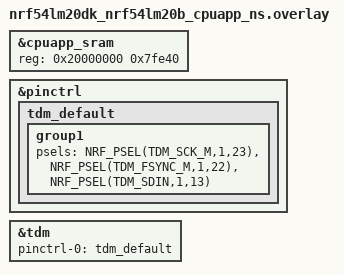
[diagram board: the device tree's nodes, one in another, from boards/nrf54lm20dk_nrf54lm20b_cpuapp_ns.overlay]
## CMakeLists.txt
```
#
# Copyright (c) 2018 Nordic Semiconductor
#
# SPDX-License-Identifier: LicenseRef-Nordic-5-Clause
#
cmake_minimum_required(VERSION 3.20.0)

find_package(Zephyr REQUIRED HINTS $ENV{ZEPHYR_BASE})
project(NONE)

# NORDIC SDK APP START
target_sources(app PRIVATE
  src/main.c
  src/beamform.c
  src/bluetooth.c
)

# NORDIC SDK APP END
```

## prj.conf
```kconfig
#
# Copyright (c) 2018 Nordic Semiconductor
#
# SPDX-License-Identifier: LicenseRef-Nordic-5-Clause
#

# Enable the UART driver
CONFIG_UART_ASYNC_API=y
CONFIG_NRFX_UARTE=y
CONFIG_SERIAL=y

CONFIG_GPIO=y

# Make sure printk is printing to the UART console
CONFIG_CONSOLE=y
CONFIG_UART_CONSOLE=y

CONFIG_HEAP_MEM_POOL_SIZE=300000
# sized for ~8 seconds of 16kHz mono audio

CONFIG_BT=y
CONFIG_BT_PERIPHERAL=y
CONFIG_BT_DEVICE_NAME="iLab-BeamformerProto"
CONFIG_BT_MAX_CONN=1
CONFIG_BT_MAX_PAIRED=1

# Enable the NUS service
CONFIG_BT_NUS=y

# Enable bonding
CONFIG_BT_SETTINGS=y
CONFIG_FLASH=y
CONFIG_FLASH_PAGE_LAYOUT=y
CONFIG_FLASH_MAP=y

# Enable DK LED and Buttons library
CONFIG_DK_LIBRARY=y

CONFIG_SYSTEM_WORKQUEUE_STACK_SIZE=2048
# Config logger
CONFIG_LOG=y
CONFIG_USE_SEGGER_RTT=y
CONFIG_LOG_BACKEND_RTT=y
CONFIG_LOG_BACKEND_UART=n
CONFIG_LOG_PRINTK=n

CONFIG_ASSERT=y

CONFIG_BT_L2CAP_TX_MTU=247
CONFIG_BT_BUF_ACL_TX_SIZE=251
CONFIG_BT_BUF_ACL_RX_SIZE=251
CONFIG_BT_CTLR_DATA_LENGTH_MAX=251

CONFIG_I2S=y
```

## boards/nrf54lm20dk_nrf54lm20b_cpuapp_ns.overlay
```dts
/*
 * Copyright (c) 2026 N›ordic Semiconductor ASA
 *
 * SPDX-License-Identifier: LicenseRef-Nordic-5-Clause
 */

 #include <dt-bindings/pinctrl/nrf-pinctrl.h>

&cpuapp_sram {
	reg = <0x20000000 0x7fe40>;
	ranges = <0x0 0x20000000 0x7fe40>;
};

&pinctrl {
	tdm_default: tdm_default {
		group1 {
			psels = <NRF_PSEL(TDM_SCK_M,1,23)>,
				<NRF_PSEL(TDM_FSYNC_M,1,22)>,
				<NRF_PSEL(TDM_SDIN,1,13)>;
		};
	};
};

&tdm {
	status = "okay";
	pinctrl-0 = <&tdm_default>;
	pinctrl-names = "default";
};
```

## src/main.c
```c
#include <zephyr/kernel.h>
#include <zephyr/logging/log.h>
#include <zephyr/sys/atomic.h>
#include <zephyr/sys/util.h>
#include <dk_buttons_and_leds.h>

#include "beamform.h"
#include "bluetooth.h"

LOG_MODULE_REGISTER(main, LOG_LEVEL_INF);

enum audio_state {
	STATE_IDLE = BIT(0),
	STATE_LISTENING = BIT(1),
	STATE_FINALIZE = BIT(2),
	STATE_PROCESSING = BIT(3),
	STATE_RESPONDING = BIT(4),
};

static atomic_t audio_state = ATOMIC_INIT(STATE_IDLE);
static atomic_t capture_enabled = ATOMIC_INIT(0);

static void enter_state(enum audio_state next_state) {
	atomic_set(&audio_state, next_state);

	switch(next_state) {
		case STATE_IDLE:
			atomic_clear(&capture_enabled);
			LOG_INF("STATE_IDLE");
			break;
		
		case STATE_LISTENING:
			atomic_set(&capture_enabled, 1);
			LOG_INF("STATE_LISTENING: capture_enabled=1");
			break;
		
		case STATE_FINALIZE:
			atomic_clear(&capture_enabled);
			LOG_INF("STATE_FINALIZE: capture_enabled=0, draining BLE TX queue");
			break;
		
		case STATE_PROCESSING:
			atomic_clear(&capture_enabled);
			LOG_INF("STATE_PROCESSING");
			break;
		
		case STATE_RESPONDING:
			atomic_clear(&capture_enabled);
			LOG_INF("STATE_RESPONDING");
			break;
		
		default:
			LOG_ERR("Invalid state: 0x%x", next_state);
			atomic_set(&audio_state, STATE_IDLE);
			atomic_clear(&capture_enabled);
			break;
	}
}

static void on_beamformed_chunk(const int16_t *samples, size_t count) {
	if (!atomic_get(&capture_enabled)) {
		return;
	}

	int err = bluetooth_enqueue_audio(samples, count);

	if(err) {
		LOG_WRN("BLE TX queue rejected audio chunk: %d", err);
	}
}

static void button_changed(uint32_t state, uint32_t changed) {
	uint32_t pressed = state & changed;
	enum audio_state current = atomic_get(&audio_state);

	// IDLE -> LISTENING
	if ((pressed & DK_BTN1_MSK) && current == STATE_IDLE) {
		enter_state(STATE_LISTENING);
	}
	
	// LISTENING -> FINALIZE
	if ((pressed & DK_BTN2_MSK) && current == STATE_LISTENING) {
		enter_state(STATE_FINALIZE);
	}
}

static void finalize_processing(void) {
	enum audio_state current = atomic_get(&audio_state);

	if(current == STATE_FINALIZE && bluetooth_tx_drained()) {
		enter_state(STATE_PROCESSING);

		// fill in other behavior for processing

		enter_state(STATE_IDLE);
	}
}

int main(void) {
	int err = dk_leds_init();
	if(err) return err;
	err = dk_buttons_init(button_changed);
	if(err) return err;
	err = bluetooth_init();
	if(err) return err;
	err = beamform_init(on_beamformed_chunk);
	if(err) return err;
	err = beamform_start();
	if(err) {
		LOG_ERR("Always-on beamforming failed to start: %d", err);
		return err;
	}

	enter_state(STATE_IDLE);
	LOG_INF("Always-on beamforming active\nBTN1: IDLE->LISTENING, BTN2: LISTENING->FINALIZE");

	for (;;) {
		finalize_processing();
		k_sleep(K_MSEC(10));
	}
}
```

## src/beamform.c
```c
#include <errno.h>
#include <zephyr/device.h>
#include <zephyr/devicetree.h>
#include <zephyr/drivers/i2s.h>
#include <zephyr/kernel.h>
#include <zephyr/logging/log.h>
#include <zephyr/sys/atomic.h>

LOG_MODULE_REGISTER(beamform);

#define SAMPLE_RATE 16000
#define CHANNELS    2
#define BLOCK_PAIRS 256
#define BLOCK_BYTES (BLOCK_PAIRS * CHANNELS * sizeof(int16_t))
#define MAX_SAMPLES (SAMPLE_RATE * 8) 

#define TDM_NODE DT_NODELABEL(tdm)

K_MEM_SLAB_DEFINE(rx_slab, BLOCK_BYTES, 4, 4);
K_THREAD_STACK_DEFINE(capture_stack, 2048);

static const struct device *const i2s = DEVICE_DT_GET(TDM_NODE);
static const struct i2s_config i2s_cfg = {
    .word_size = 16,
    .channels = CHANNELS,
    .format = I2S_FMT_DATA_FORMAT_I2S,
    .options = I2S_OPT_BIT_CLK_CONT | I2S_OPT_FRAME_CLK_MASTER,
    .frame_clk_freq = SAMPLE_RATE,
    .mem_slab = &rx_slab,
    .block_size = BLOCK_BYTES,
    .timeout = 2000,
};

static int16_t mono[MAX_SAMPLES];
static size_t mono_count;
static atomic_t recording = ATOMIC_INIT(0);
static atomic_t audio_ready = ATOMIC_INIT(0);
static struct k_thread capture_thread_data;
static void (*recording_done)(void);

static void capture(void *a, void *b, void *c) {
    ARG_UNUSED(a);
    ARG_UNUSED(b);
    ARG_UNUSED(c);

    if(i2s_trigger(i2s, I2S_DIR_RX, I2S_TRIGGER_START)) {
        atomic_clear(&recording);
        return;
    }

    while (atomic_get(&recording) && mono_count < MAX_SAMPLES) {
        void *block;
        size_t bytes;
        int err = i2s_read(i2s, &block, &bytes);

        if(err) {
            if (err == -EAGAIN) {
                continue;
            }
            break;
        }

        int16_t *stereo = block;
        size_t pairs = bytes/ (CHANNELS * sizeof(int16_t));
        for (size_t i =0; i < pairs && mono_count < MAX_SAMPLES; i++) {
            // beamforming algorithm:
            mono[mono_count++] = ((int32_t)stereo[2*i] + stereo[2*i+1])/2;
        }
        k_mem_slab_free(&rx_slab, block);
    }

    i2s_trigger(i2s, I2S_DIR_RX, I2S_TRIGGER_DROP);
    atomic_clear(&recording);
    atomic_set(&audio_ready, 1);
    if(recording_done) {
        recording_done();
    }
}

int beamform_init(void (*done_cb)(void)) {
    recording_done = done_cb;
    if(!device_is_ready(i2s)) {
        return -ENODEV;
    }
    return i2s_configure(i2s, I2S_DIR_RX, &i2s_cfg);
}

int beamform_start(void) {
    if(atomic_get(&recording) || atomic_get(&audio_ready)) {
        return -EBUSY;
    }

    mono_count = 0;
    atomic_set(&recording,1);
    k_thread_create(&capture_thread_data, capture_stack, 
        K_THREAD_STACK_SIZEOF(capture_stack), capture, NULL, NULL, NULL,
        6, 0, K_NO_WAIT);
    return 0;
}

void beamform_stop(void) {
    atomic_clear(&recording);
    i2s_trigger(i2s, I2S_DIR_RX, I2S_TRIGGER_DROP);
}

bool beamform_has_audio(void) {
    return atomic_get(&audio_ready);
}

const int16_t *beamform_audio(void) {
    return mono;
}

size_t beamform_audio_count(void) {
    return mono_count;
}

void beamform_clear(void) {
    mono_count = 0;
    atomic_clear(&audio_ready);
}
```

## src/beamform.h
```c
#ifndef BEAMFORM_H_
#define BEAMFORM_H_

#include <stddef.h>
#include <stdint.h>
#include <stdbool.h>

int beamform_init(void (*done_cb)(void));
int beamform_start(void);
void beamform_stop(void);

bool beamform_has_audio(void);
const int16_t *beamform_audio(void);
size_t beamform_audio_count(void);
void beamform_clear(void);

#endif
```

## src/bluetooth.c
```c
#include <errno.h>
#include <string.h>
#include <zephyr/bluetooth/bluetooth.h>
#include <zephyr/bluetooth/conn.h>
#include <zephyr/bluetooth/gatt.h>
#include <zephyr/kernel.h>
#include <zephyr/logging/log.h>
#include <zephyr/sys/atomic.h>
#include <bluetooth/services/nus.h>

#include "bluetooth.h"

LOG_MODULE_REGISTER(bluetooth, LOG_LEVEL_INF);

#define DEVICE_NAME CONFIG_BT_DEVICE_NAME
#define DEVICE_NAME_LEN (sizeof(DEVICE_NAME) - 1)

#define AUDIO_CHUNK_SAMPLES 256
#define AUDIO_QUEUE_DEPTH 8

struct audio_chunk {
    size_t samples;
    int16_t pcm[AUDIO_CHUNK_SAMPLES];
};

K_MSGQ_DEFINE(audio_tx_queue, sizeof(struct audio_chunk), AUDIO_QUEUE_DEPTH, 4);
K_THREAD_STACK_DEFINE(ble_tx_stack, 2048);

static struct bt_conn *connection;
static atomic_t subscribed = ATOMIC_INIT(0);
static atomic_t tx_busy = ATOMIC_INIT(0);
static struct k_thread ble_tx_thread_data;

static const struct bt_data ad[] = {
    BT_DATA_BYTES(BT_DATA_FLAGS, BT_LE_AD_GENERAL | BT_LE_AD_NO_BREDR),
    BT_DATA(BT_DATA_NAME_COMPLETE, DEVICE_NAME, DEVICE_NAME_LEN),
};
static const struct bt_data sd[] = {
    BT_DATA_BYTES(BT_DATA_UUID128_ALL, BT_UUID_NUS_VAL),
};

static bool bluetooth_ready(void) {
    return connection != NULL && atomic_get(&subscribed);
}

static void connected(struct bt_conn *conn, uint8_t err) {
    if(err) {
        LOG_WRN("BLE connection failed: %u", err);
        return;
    }

    connection = bt_conn_ref(conn);
    LOG_INF("BLE connected");
}

static void disconnected(struct bt_conn *conn, uint8_t reason) {
    ARG_UNUSED(conn);
    ARG_UNUSED(reason);

    atomic_clear(&subscribed);

    if(connection) {
        bt_conn_unref(connection);
        connection = NULL;
    }

    LOG_INF("BLE disconnected");
    bt_le_adv_start(BT_LE_ADV_CONN_FAST_2, ad, ARRAY_SIZE(ad), sd, 
        ARRAY_SIZE(sd));
}

BT_CONN_CB_DEFINE(conn_callbacks) = {
    .connected = connected,
    .disconnected = disconnected,
};

static void nus_send_enabled(enum bt_nus_send_status status) {
    atomic_set(&subscribed, status == BT_NUS_SEND_STATUS_ENABLED);
    LOG_INF("NUS notifications %s", atomic_get(&subscribed) ? "enabled" : "disabled");
}

static struct bt_nus_cb nus_cb = {
    .send_enabled = nus_send_enabled,
};

static int send_chunk(const struct audio_chunk *chunk) {
    if (!bluetooth_ready()) {
        return -ENOTCONN;
    }

    uint16_t mtu = bt_gatt_get_mtu(connection);
    size_t samples_per_packet = MAX((size_t)1, (mtu-3) / sizeof(int16_t));

    for(size_t offset = 0; offset < chunk->samples; offset += samples_per_packet) {
        size_t count = MIN(samples_per_packet, chunk->samples - offset);
        int err = bt_nus_send(NULL, (const uint8_t *)&chunk->pcm[offset], count*sizeof(int16_t));

        if(err) return err;

        k_sleep(K_MSEC(1));
    }

    return 0;
}


static void ble_tx_worker(void *a, void *b, void *c) {
    ARG_UNUSED(a);
    ARG_UNUSED(b);
    ARG_UNUSED(c);

    while(true) {
        struct audio_chunk chunk;
        int err = k_msgq_get(&audio_tx_queue, &chunk, K_FOREVER);
        if (err) continue;

        atomic_set(&tx_busy, 1);

        while(!bluetooth_ready()) {
            k_sleep(K_MSEC(20));
        }

        err = send_chunk(&chunk);
        if(err) {
            LOG_WRN("BLE send failed; dropped one chunk: %d", err);
        }

        atomic_clear(&tx_busy);
    }
}

int bluetooth_init(void) {
    int err = bt_enable(NULL);
    if(err) {
        return err;
    }

    err = bt_nus_init(&nus_cb);
    if(err) {
        return err;
    }

    k_thread_create(&ble_tx_thread_data, ble_tx_stack, 
        K_THREAD_STACK_SIZEOF(ble_tx_stack), ble_tx_worker,
        NULL, NULL, NULL, 7, 0, K_NO_WAIT);

    return bt_le_adv_start(BT_LE_ADV_CONN_FAST_2, ad, ARRAY_SIZE(ad), 
        sd, ARRAY_SIZE(sd));
}

int bluetooth_enqueue_audio(const int16_t *samples, size_t count) {
    if(count==0 || count > AUDIO_CHUNK_SAMPLES) {
        return -EINVAL;
    }

    if(!bluetooth_ready()) {
        return -ENOTCONN;
    }

    struct audio_chunk chunk = {
        .samples = count,
    };

    memcpy(chunk.pcm, samples, count*sizeof(int16_t));
    
    return k_msgq_put(&audio_tx_queue, &chunk, K_NO_WAIT);
}

bool bluetooth_tx_drained(void) {
    return k_msgq_num_used_get(&audio_tx_queue) == 0 && !atomic_get(&tx_busy);
}
```

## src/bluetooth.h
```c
#ifndef BLUETOOTH_H_
#define BLUETOOTH_H_

#include <stdbool.h>
#include <stddef.h>
#include <stdint.h>

typedef void (*bluetooth_ready_cb_t)(void);

int bluetooth_init(bluetooth_ready_cb_t ready_cb);
bool bluetooth_can_send(void);

int bluetooth_send_pcm(const int16_t *samples, size_t sample_count);

#endif
```
